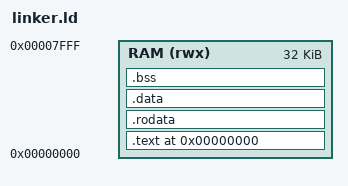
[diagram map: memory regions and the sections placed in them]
OUTPUT_ARCH(riscv)
ENTRY(_start)

MEMORY
{
    RAM (rwx) : ORIGIN = 0x00000000, LENGTH = 32K
}

SECTIONS
{
    . = ORIGIN(RAM);

    .text : ALIGN(4)
    {
        KEEP(*(.text.start))
        *(.text .text.*)
    } > RAM

    .rodata : ALIGN(4)
    {
        *(.rodata .rodata.*)
    } > RAM

    .data : ALIGN(4)
    {
        *(.data .data.*)
        *(.sdata .sdata.*)
    } > RAM

    PROVIDE(__global_pointer$ = . + 0x800);

    .bss (NOLOAD) : ALIGN(4)
    {
        __bss_start = .;
        *(.sbss .sbss.*)
        *(.bss .bss.*)
        *(COMMON)
        . = ALIGN(4);
        __bss_end = .;
    } > RAM

    __image_end   = .;
    __stack_size  = 1K;
    __stack_top   = ORIGIN(RAM) + LENGTH(RAM);
    __stack_bottom = __stack_top - __stack_size;

    ASSERT(__image_end <= __stack_bottom,
           "Firmware image overlaps the stack")
}

